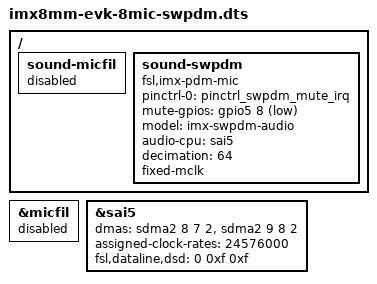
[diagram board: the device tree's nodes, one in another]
// SPDX-License-Identifier: (GPL-2.0 OR MIT)
/*
 * Copyright 2020 NXP
 */

#include "imx8mm-evk-8mic-revE.dts"

/ {
	sound-micfil {
		status = "disabled";
	};

	sound-swpdm {
		compatible = "fsl,imx-pdm-mic";
		pinctrl-names = "default";
		pinctrl-0 = <&pinctrl_swpdm_mute_irq>;
		mute-gpios = <&gpio5 8 GPIO_ACTIVE_LOW>;
		model = "imx-swpdm-audio";
		audio-cpu = <&sai5>;
		decimation = <64>;
		status = "okay";
		fixed-mclk;
	};
};

&micfil {
	status = "disabled";
};

&sai5 {
	dmas = <&sdma2 8 7 2>, <&sdma2 9 8 2>;
	assigned-clock-rates = <24576000>;
	fsl,dataline,dsd = <0 0xf 0xf>;
	status = "okay";
};
